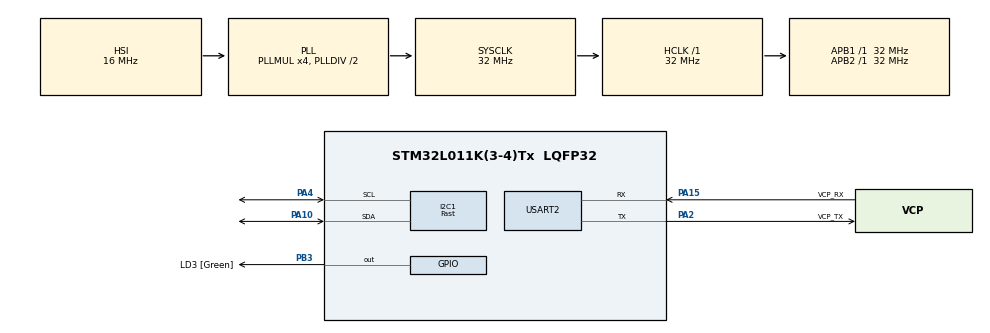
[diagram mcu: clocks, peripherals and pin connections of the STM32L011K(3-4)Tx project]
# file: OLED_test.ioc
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I2C1.I2C_Speed_Mode=I2C_Fast
I2C1.Timing=0x00300F38
Mcu.Family=STM32L0
Mcu.Name=STM32L011K(3-4)Tx
Mcu.Package=LQFP32
PA10.Mode=I2C
PA10.Signal=I2C1_SDA
PA13.GPIO_Label=TMS
PA13.Mode=Serial_Wire
PA13.Signal=SYS_SWDIO
PA14.GPIO_Label=TCK
PA14.Mode=Serial_Wire
PA14.Signal=SYS_SWCLK
PA15.GPIO_Label=VCP_RX
PA15.Mode=Asynchronous
PA15.Signal=USART2_RX
PA2.GPIO_Label=VCP_TX
PA2.Mode=Asynchronous
PA2.Signal=USART2_TX
PA4.Mode=I2C
PA4.Signal=I2C1_SCL
PB3.GPIO_Label=LD3 [Green]
PB3.Signal=GPIO_Output
PC15-OSC32_OUT.Signal=RCC_OSC32_OUT
ProjectManager.HeapSize=0x0
ProjectManager.StackSize=0x100
ProjectManager.TargetToolchain=STM32CubeIDE
RCC.AHBFreq_Value=32000000
RCC.APB1Freq_Value=32000000
RCC.APB1TimFreq_Value=32000000
RCC.APB2Freq_Value=32000000
RCC.APB2TimFreq_Value=32000000
RCC.HCLKFreq_Value=32000000
RCC.HSE_VALUE=8000000
RCC.HSI16_VALUE=16000000
RCC.HSI48_VALUE=48000000
RCC.HSI_VALUE=16000000
RCC.LSE_VALUE=32768
RCC.MSI_VALUE=2097000
RCC.PLLMUL=RCC_PLLMUL_4
RCC.SYSCLKFreq_VALUE=32000000
RCC.SYSCLKSource=RCC_SYSCLKSOURCE_PLLCLK
RCC.VCOOutputFreq_Value=64000000
USART2.VirtualMode-Asynchronous=VM_ASYNC
board=NUCLEO-L011K4

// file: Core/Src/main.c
/* USER CODE BEGIN Header */
/**
  ******************************************************************************
  * @file           : main.c
  * @brief          : Main program body
  ******************************************************************************
  * @attention
  *
  * <h2><center>&copy; Copyright (c) 2021 STMicroelectronics.
  * All rights reserved.</center></h2>
  *
  * This software component is licensed by ST under BSD 3-Clause license,
  * the "License"; You may not use this file except in compliance with the
  * License. You may obtain a copy of the License at:
  *                        opensource.org/licenses/BSD-3-Clause
  *
  ******************************************************************************
  */
/* USER CODE END Header */
#include "main.h"
#include "i2c.h"
#include "usart.h"
#include "gpio.h"

/* USER CODE BEGIN Includes */
#include "oled096.h"
/* USER CODE END Includes */

void SystemClock_Config(void);

int main(void)
{

  /* MCU Configuration--------------------------------------------------------*/

  /* Reset of all peripherals, Initializes the Flash interface and the Systick. */
  HAL_Init();

  /* Configure the system clock */
  SystemClock_Config();

  /* Initialize all configured peripherals */
  MX_GPIO_Init();
  MX_USART2_UART_Init();
  MX_I2C1_Init();
  /* USER CODE BEGIN 2 */

  OLED_Init(&OLED096);
  OLED_DrawTestImage(&OLED096);
  OLED_FrameRefresh (&OLED096);

  /* USER CODE END 2 */

  /* Infinite loop */
  while (1)
  {

  }
}

void SystemClock_Config(void)
{
  RCC_OscInitTypeDef RCC_OscInitStruct = {0};
  RCC_ClkInitTypeDef RCC_ClkInitStruct = {0};
  RCC_PeriphCLKInitTypeDef PeriphClkInit = {0};

  /** Configure the main internal regulator output voltage
  */
  __HAL_PWR_VOLTAGESCALING_CONFIG(PWR_REGULATOR_VOLTAGE_SCALE1);
  /** Initializes the RCC Oscillators according to the specified parameters
  * in the RCC_OscInitTypeDef structure.
  */
  RCC_OscInitStruct.OscillatorType = RCC_OSCILLATORTYPE_HSI;
  RCC_OscInitStruct.HSIState = RCC_HSI_ON;
  RCC_OscInitStruct.HSICalibrationValue = RCC_HSICALIBRATION_DEFAULT;
  RCC_OscInitStruct.PLL.PLLState = RCC_PLL_ON;
  RCC_OscInitStruct.PLL.PLLSource = RCC_PLLSOURCE_HSI;
  RCC_OscInitStruct.PLL.PLLMUL = RCC_PLLMUL_4;
  RCC_OscInitStruct.PLL.PLLDIV = RCC_PLLDIV_2;
  if (HAL_RCC_OscConfig(&RCC_OscInitStruct) != HAL_OK)
  {
    Error_Handler();
  }
  /** Initializes the CPU, AHB and APB buses clocks
  */
  RCC_ClkInitStruct.ClockType = RCC_CLOCKTYPE_HCLK|RCC_CLOCKTYPE_SYSCLK
                              |RCC_CLOCKTYPE_PCLK1|RCC_CLOCKTYPE_PCLK2;
  RCC_ClkInitStruct.SYSCLKSource = RCC_SYSCLKSOURCE_PLLCLK;
  RCC_ClkInitStruct.AHBCLKDivider = RCC_SYSCLK_DIV1;
  RCC_ClkInitStruct.APB1CLKDivider = RCC_HCLK_DIV1;
  RCC_ClkInitStruct.APB2CLKDivider = RCC_HCLK_DIV1;

  if (HAL_RCC_ClockConfig(&RCC_ClkInitStruct, FLASH_LATENCY_1) != HAL_OK)
  {
    Error_Handler();
  }
  PeriphClkInit.PeriphClockSelection = RCC_PERIPHCLK_USART2|RCC_PERIPHCLK_I2C1;
  PeriphClkInit.Usart2ClockSelection = RCC_USART2CLKSOURCE_PCLK1;
  PeriphClkInit.I2c1ClockSelection = RCC_I2C1CLKSOURCE_PCLK1;
  if (HAL_RCCEx_PeriphCLKConfig(&PeriphClkInit) != HAL_OK)
  {
    Error_Handler();
  }
}

void Error_Handler(void)
{
  __disable_irq();
  while (1)
  {
  }
}

/************************ (C) COPYRIGHT STMicroelectronics *****END OF FILE****/
